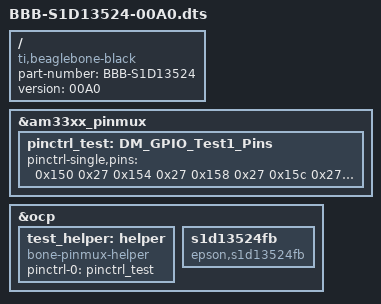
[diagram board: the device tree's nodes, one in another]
/*
* Copyright (C) 2013 Seiko Epson
*
* This program is free software; you can redistribute it and/or modify
* it under the terms of the GNU General Public License version 2 as
* published by the Free Software Foundation.
*/
/dts-v1/;
/plugin/;

/ {
	compatible = "ti,beaglebone-black";
	part-number = "BBB-S1D13524";
	version = "00A0";

       fragment@0 {
             target = <&am33xx_pinmux>;
            
             __overlay__ {
                  pinctrl_test: DM_GPIO_Test1_Pins {
			pinctrl-single,pins = <
                 
                0x150 0x27
                0x154 0x27
                0x158 0x27
                0x15c 0x27
				0x1a4 0x37
         				
			>;
		  };
             };
       };
     
	   fragment@1 {
		target = <&ocp>;
		__overlay__ {
                     
			test_helper: helper {
                                compatible = "bone-pinmux-helper";
                                pinctrl-names = "default";
                                pinctrl-0 = <&pinctrl_test>;
                                status = "okay";
                        };
		
			s1d13524fb {
				compatible = "epson,s1d13524fb";
			};
		};
	};
	
};
